# SIM3L166_C register map
File version: 1
CPU: 
Registers are 32-bit, read-write, reset 0x0 unless marked. A register's access mark holds for its fields unless they carry their own. Offsets are from the block's base; [hi:lo] are bit positions; 'fields as' and 'values as' point back to an identical list.

## PBCFG_0
Base 0x4002A000
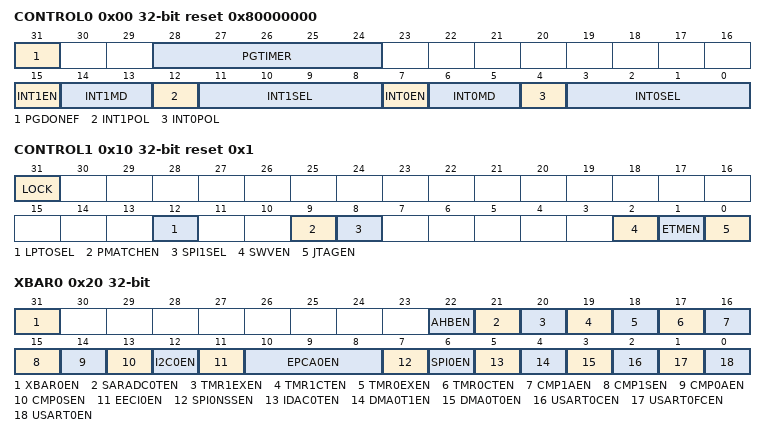
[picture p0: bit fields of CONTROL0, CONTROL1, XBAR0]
0x00 CONTROL0 reset 0x80000000 — Global Port Control 0
  [31] PGDONEF ro — Pulse Generator Timer Done Flag.
    0=NOT_SET (Firmware has written to the PBPGPHASE register, but the Pulse Generator timer has not expired.); 1=SET (The Pulse Generator cycle finished since the last time PBPGPHASE was written.)
  [28:24] PGTIMER — Pulse Generator Timer.
  [15] INT1EN — External Interrupt 1 Enable.
    0=DISABLED (Disable external interrupt 1.); 1=ENABLED (Enable external interrupt 1.)
  [14:13] INT1MD — External Interrupt 1 Mode.
    0=LEVEL (Interrupt on logic level at pin, as selected by the INT1POL field.); 1=EDGE (Interrupt on either rising or falling edge, as selected by the INT1POL field.); 2=DUAL_EDGE (Interrupt on both rising and falling edges (ignores INT1POL).)
  [12] INT1POL — External Interrupt 1 Polarity.
    0=LOW (A low value or falling edge on the selected pin will cause interrupt.); 1=HIGH (A high value or rising edge on the selected pin will cause interrupt.)
  [11:8] INT1SEL — External Interrupt 1 Pin Selection.
    0=INT1_0 (Select INT1.0); 1=INT1_1 (Select INT1.1); 2=INT1_2 (Select INT1.2); 3=INT1_3 (Select INT1.3); 4=INT1_4 (Select INT1.4); 5=INT1_5 (Select INT1.5); 6=INT1_6 (Select INT1.6); 7=INT1_7 (Select INT1.7); 8=INT1_8 (Select INT1.8); 9=INT1_9 (Select INT1.9); 10=INT1_10 (Select INT1.10); 11=INT1_11 (Select INT1.11); 12=INT1_12 (Select INT1.12); 13=INT1_13 (Select INT1.13); 14=INT1_14 (Select INT1.14); 15=INT1_15 (Select INT1.15)
  [7] INT0EN — External Interrupt 0 Enable.
    0=DISABLED (Disable external interrupt 0.); 1=ENABLED (Enable external interrupt 0.)
  [6:5] INT0MD — External Interrupt 0 Mode.
    0=LEVEL (Interrupt on logic level at pin, as selected by the INT0POL field.); 1=EDGE (Interrupt on either rising or falling edge, as selected by the INT0POL field.); 2=DUAL_EDGE (Interrupt on both rising and falling edges (ignores INT0POL).)
  [4] INT0POL — External Interrupt 0 Polarity.
    values as INT1POL
  [3:0] INT0SEL — External Interrupt 0 Pin Selection.
    0=INT0_0 (Select INT0.0); 1=INT0_1 (Select INT0.1); 2=INT0_2 (Select INT0.2); 3=INT0_3 (Select INT0.3); 4=INT0_4 (Select INT0.4); 5=INT0_5 (Select INT0.5); 6=INT0_6 (Select INT0.6); 7=INT0_7 (Select INT0.7); 8=INT0_8 (Select INT0.8); 9=INT0_9 (Select INT0.9); 10=INT0_10 (Select INT0.10); 11=INT0_11 (Select INT0.11); 12=INT0_12 (Select INT0.12); 13=INT0_13 (Select INT0.13); 14=INT0_14 (Select INT0.14); 15=INT0_15 (Select INT0.15)
0x10 CONTROL1 reset 0x1 — Global Port Control 1
  [31] LOCK — Port Bank Configuration Lock.
    0=UNLOCKED (Port Bank Configuration and Control registers are unlocked.); 1=LOCKED (The following registers are locked from write access: CONTROL1, XBAR0, and all PBSKIP registers.)
  [12] LPTOSEL — Low Power Timer Output Pin Select.
    0=LPT0OUT0 (Route the Low Power Timer output to LPT0OUT0.); 1=LPT0OUT1 (Route the Low Power Timer output to LPT0OUT1.)
  [9] PMATCHEN — Port Match Interrupt Enable.
    0=DISABLED (Disable the port match logic. The PBnMAT registers are not read/write accessible on the APB bus.); 1=ENABLED (Enable the port match logic to generate a port match interrupt. The PBnMAT registers are read/write accessible on the APB bus.)
  [8] SPI1SEL — SPI1 Fixed Port Selection.
    0=DISABLED (Disconnect SPI1 from the dedicated pins.); 1=ENABLED (Connect SPI1 to the dedicated pins.)
  [2] SWVEN — SWV Enable.
    0=DISABLED (SWV is not pinned out.); 1=ENABLED (SWV is enabled and pinned out.)
  [1] ETMEN — ETM Enable.
    0=DISABLED (ETM not pinned out.); 1=ENABLED (ETM is enabled and pinned out.)
  [0] JTAGEN — JTAG Enable.
    0=DISABLED (JTAG functionality is not pinned out.); 1=ENABLED (JTAG functionality is pinned out.)
0x20 XBAR0 — Crossbar 0 Control
  [31] XBAR0EN — Crossbar 0 Enable.
    0=DISABLED (Disable Crossbar 0.); 1=ENABLED (Enable Crossbar 0.)
  [22] AHBEN — AHB Clock Output Enable.
    0=DISABLED (Disable the AHB Clock / 16 output on Crossbar 0.); 1=ENABLED (Enable the AHB Clock / 16 output on Crossbar 0.)
  [21] SARADC0TEN — SARADC0 Trigger Enable.
    0=DISABLED (Disable SARADC0 conversion start trigger on Crossbar 0.); 1=ENABLED (Enable SARADC0 conversion start trigger on Crossbar 0.)
  [20] TMR1EXEN — TIMER1 T1EX Enable.
    0=DISABLED (Disable TIMER1 EX on Crossbar 0.); 1=ENABLED (Enable TIMER1 EX on Crossbar 0.)
  [19] TMR1CTEN — TIMER1 T1CT Enable.
    0=DISABLED (Disable TIMER1 CT on Crossbar 0.); 1=ENABLED (Enable TIMER1 CT on Crossbar 0.)
  [18] TMR0EXEN — TIMER0 T0EX Enable.
    0=DISABLED (Disable TIMER0 EX on Crossbar 0.); 1=ENABLED (Enable TIMER0 EX on Crossbar 0.)
  [17] TMR0CTEN — TIMER0 T0CT Enable.
    0=DISABLED (Disable TIMER0 CT on Crossbar 0.); 1=ENABLED (Enable TIMER0 CT on Crossbar 0.)
  [16] CMP1AEN — Comparator 1 Asynchronous Output (CMP1A) Enable.
    0=DISABLED (Disable Comparator 1 Asynchronous Output (CMP1A) on Crossbar 0.); 1=ENABLED (Enable Comparator 1 Asynchronous Output (CMP1A) on Crossbar 0.)
  [15] CMP1SEN — Comparator 1 Synchronous Output (CMP1S) Enable.
    0=DISABLED (Disable Comparator 1 Synchronous Output (CMP1S) on Crossbar 0.); 1=ENABLED (Enable Comparator 1 Synchronous Output (CMP1S) on Crossbar 0.)
  [14] CMP0AEN — Comparator 0 Asynchronous Output (CMP0A) Enable.
    0=DISABLED (Disable Comparator 0 Asynchronous Output (CMP0A) on Crossbar 0.); 1=ENABLED (Enable Comparator 0 Asynchronous Output (CMP0A) on Crossbar 0.)
  [13] CMP0SEN — Comparator 0 Synchronous Output (CMP0S) Enable.
    0=DISABLED (Disable Comparator 0 Synchronous Output (CMP0S) on Crossbar 0.); 1=ENABLED (Enable Comparator 0 Synchronous Output (CMP0S) on Crossbar 0.)
  [12] I2C0EN — I2C0 Enable.
    0=DISABLED (Disable I2C0 SDA and SCL on Crossbar 0.); 1=ENABLED (Enable I2C0 SDA and SCL on Crossbar 0.)
  [11] EECI0EN — EPCA0 ECI Enable.
    0=DISABLED (Disable EPCA0 ECI on Crossbar 0.); 1=ENABLED (Enable EPCA0 ECI on Crossbar 0.)
  [10:8] EPCA0EN — EPCA0 Channel Enable.
    0=NONE (Disable all EPCA0 channels on Crossbar 0.); 1=CEX0_0 (Enable EPCA0 CEX0 on Crossbar 0.); 2=CEX0_1 (Enable EPCA0 CEX0 and CEX1 on Crossbar 0.); 3=CEX0_2 (Enable EPCA0 CEX0, CEX1, and CEX2 on Crossbar 0.); 4=CEX0_3 (Enable EPCA0 CEX0, CEX1, CEX2, and CEX3 on Crossbar 0.); 5=CEX0_4 (Enable EPCA0 CEX0, CEX1, CEX2, CEX3, and CEX4 on Crossbar 0.); 6=CEX0_5 (Enable EPCA0 CEX0, CEX1, CEX2, CEX3, CEX4, and CEX5 on Crossbar 0.)
  [7] SPI0NSSEN — SPI0 NSS Pin Enable.
    0=DISABLED (Disable SPI0 NSS on Crossbar 0.); 1=ENABLED (Enable SPI0 NSS on Crossbar 0.)
  [6] SPI0EN — SPI0 Enable.
    0=DISABLED (Disable SPI0 SCK, MISO, and MOSI on Crossbar 0.); 1=ENABLED (Enable SPI0 SCK, MISO, and MOSI on Crossbar 0.)
  [5] IDAC0TEN — IDAC0 Trigger Enable.
    0=DISABLED (Disable the IDAC0 trigger on Crossbar 0.); 1=ENABLED (Enable the IDAC0 trigger on Crossbar 0.)
  [4] DMA0T1EN — DMA Trigger 1 Enabled.
    0=DISABLED (Disable the DMA trigger 1 on Crossbar 0.); 1=ENABLED (Enable the DMA trigger 1 on Crossbar 0.)
  [3] DMA0T0EN — DMA Trigger 0 Enable.
    0=DISABLED (Disable the DMA trigger 0 on Crossbar 0.); 1=ENABLED (Enable the DMA trigger 0 on Crossbar 0.)
  [2] USART0CEN — USART0 Clock Signal Enable.
    0=DISABLED (Disable USART0 clock on Crossbar 0.); 1=ENABLED (Enable USART0 clock on Crossbar 0.)
  [1] USART0FCEN — USART0 Flow Control Enable.
    0=DISABLED (Disable USART0 flow control on Crossbar 0.); 1=ENABLED (Enable USART0 flow control on Crossbar 0.)
  [0] USART0EN — USART0 Enable.
    0=DISABLED (Disable USART0 RX and TX on Crossbar 0.); 1=ENABLED (Enable USART0 RX and TX on Crossbar 0.)
0x30 PBKEY — Global Port Key
  [7:0] KEY — Port Bank Key.
    0=LOCKED (Port Bank registers are locked and no valid values have been written to PBKEY.); 1=INTERMEDIATE (Port Bank registers are locked and the first valid value (0xA5) has been written to PBKEY.); 2=UNLOCKED (Port Bank registers are unlocked. Any subsequent writes to the Port Bank registers or PBKEY will lock the interface.)
